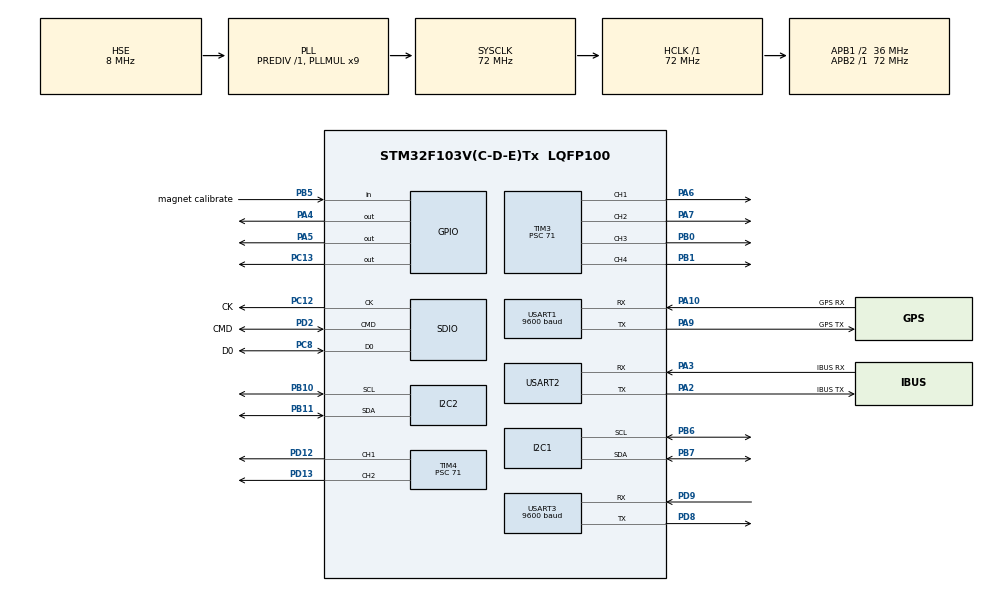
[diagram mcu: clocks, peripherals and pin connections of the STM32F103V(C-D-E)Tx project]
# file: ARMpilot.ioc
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Dma.Request0=USART2_RX
Dma.Request1=SDIO
Dma.SDIO.1.Direction=DMA_MEMORY_TO_PERIPH
Dma.SDIO.1.Instance=DMA2_Channel4
Dma.SDIO.1.MemDataAlignment=DMA_MDATAALIGN_WORD
Dma.SDIO.1.MemInc=DMA_MINC_ENABLE
Dma.SDIO.1.Mode=DMA_CIRCULAR
Dma.SDIO.1.PeriphDataAlignment=DMA_PDATAALIGN_WORD
Dma.SDIO.1.PeriphInc=DMA_PINC_DISABLE
Dma.SDIO.1.Priority=DMA_PRIORITY_LOW
Dma.USART2_RX.0.Direction=DMA_PERIPH_TO_MEMORY
Dma.USART2_RX.0.Instance=DMA1_Channel6
Dma.USART2_RX.0.MemDataAlignment=DMA_MDATAALIGN_BYTE
Dma.USART2_RX.0.MemInc=DMA_MINC_ENABLE
Dma.USART2_RX.0.Mode=DMA_CIRCULAR
Dma.USART2_RX.0.PeriphDataAlignment=DMA_PDATAALIGN_BYTE
Dma.USART2_RX.0.PeriphInc=DMA_PINC_DISABLE
Dma.USART2_RX.0.Priority=DMA_PRIORITY_LOW
FATFS._MAX_SS=4096
FATFS._MIN_SS=512
FATFS._USE_LFN=1
I2C1.I2C_Mode=I2C_Fast
I2C2.I2C_Mode=I2C_Fast
Mcu.Family=STM32F1
Mcu.Name=STM32F103V(C-D-E)Tx
Mcu.Package=LQFP100
NVIC.DMA1_Channel6_IRQn=true\:0\:0\:false\:false\:true\:false\:true\:true
NVIC.DMA2_Channel4_5_IRQn=true\:0\:0\:false\:false\:true\:false\:true\:true
NVIC.PriorityGroup=NVIC_PRIORITYGROUP_4
NVIC.SDIO_IRQn=true\:0\:0\:false\:false\:true\:true\:true\:true
NVIC.TIM6_IRQn=true\:0\:0\:false\:false\:true\:true\:true\:true
NVIC.TIM7_IRQn=true\:5\:0\:true\:false\:true\:true\:true\:true
NVIC.USART1_IRQn=true\:1\:0\:true\:false\:true\:true\:true\:true
NVIC.USART2_IRQn=true\:1\:0\:true\:false\:true\:true\:true\:true
NVIC.USART3_IRQn=true\:1\:0\:true\:false\:true\:true\:true\:true
OSC_IN.Mode=HSE-External-Oscillator
OSC_IN.Signal=RCC_OSC_IN
OSC_OUT.Mode=HSE-External-Oscillator
OSC_OUT.Signal=RCC_OSC_OUT
PA10.GPIO_Label=GPS RX
PA10.Mode=Asynchronous
PA10.Signal=USART1_RX
PA13.Mode=Serial_Wire
PA13.Signal=SYS_JTMS-SWDIO
PA14.Mode=Serial_Wire
PA14.Signal=SYS_JTCK-SWCLK
PA2.GPIO_Label=IBUS TX
PA2.Mode=Asynchronous
PA2.Signal=USART2_TX
PA3.GPIO_Label=IBUS RX
PA3.Mode=Asynchronous
PA3.Signal=USART2_RX
PA4.Signal=GPIO_Output
PA5.Signal=GPIO_Output
PA6.Signal=S_TIM3_CH1
PA7.Signal=S_TIM3_CH2
PA9.GPIO_Label=GPS TX
PA9.Mode=Asynchronous
PA9.Signal=USART1_TX
PB0.Signal=S_TIM3_CH3
PB1.Signal=S_TIM3_CH4
PB10.Mode=I2C
PB10.Signal=I2C2_SCL
PB11.Mode=I2C
PB11.Signal=I2C2_SDA
PB5.GPIO_Label=magnet calibrate
PB5.GPIO_PuPd=GPIO_PULLDOWN
PB5.Signal=GPIO_Input
PB6.Mode=I2C
PB6.Signal=I2C1_SCL
PB7.Mode=I2C
PB7.Signal=I2C1_SDA
PC12.GPIO_Label=CK
PC12.Mode=SD_1_bit
PC12.Signal=SDIO_CK
PC13-TAMPER-RTC.Signal=GPIO_Output
PC8.GPIO_Label=D0
PC8.Mode=SD_1_bit
PC8.Signal=SDIO_D0
PD12.Signal=S_TIM4_CH1
PD13.Signal=S_TIM4_CH2
PD2.GPIO_Label=CMD
PD2.Mode=SD_1_bit
PD2.Signal=SDIO_CMD
PD8.Mode=Asynchronous
PD8.Signal=USART3_TX
PD9.Mode=Asynchronous
PD9.Signal=USART3_RX
ProjectManager.HeapSize=0x1000
ProjectManager.StackSize=0x2000
ProjectManager.TargetToolchain=MDK-ARM V5.32
RCC.AHBFreq_Value=72000000
RCC.APB1CLKDivider=RCC_HCLK_DIV2
RCC.APB1Freq_Value=36000000
RCC.APB1TimFreq_Value=72000000
RCC.APB2Freq_Value=72000000
RCC.APB2TimFreq_Value=72000000
RCC.HCLKFreq_Value=72000000
RCC.PLLMUL=RCC_PLL_MUL9
RCC.PLLSourceVirtual=RCC_PLLSOURCE_HSE
RCC.SYSCLKFreq_VALUE=72000000
RCC.SYSCLKSource=RCC_SYSCLKSOURCE_PLLCLK
RCC.USBFreq_Value=72000000
SDIO.ClockDiv=2
SH.S_TIM3_CH1.0=TIM3_CH1,PWM Generation1 CH1
SH.S_TIM3_CH2.0=TIM3_CH2,PWM Generation2 CH2
SH.S_TIM3_CH3.0=TIM3_CH3,PWM Generation3 CH3
SH.S_TIM3_CH4.0=TIM3_CH4,PWM Generation4 CH4
SH.S_TIM4_CH1.0=TIM4_CH1,PWM Generation1 CH1
SH.S_TIM4_CH2.0=TIM4_CH2,PWM Generation2 CH2
TIM3.Channel-PWM\ Generation1\ CH1=TIM_CHANNEL_1
TIM3.Channel-PWM\ Generation2\ CH2=TIM_CHANNEL_2
TIM3.Channel-PWM\ Generation3\ CH3=TIM_CHANNEL_3
TIM3.Channel-PWM\ Generation4\ CH4=TIM_CHANNEL_4
TIM3.Prescaler=71
TIM4.Channel-PWM\ Generation1\ CH1=TIM_CHANNEL_1
TIM4.Channel-PWM\ Generation2\ CH2=TIM_CHANNEL_2
TIM4.Prescaler=71
TIM6.AutoReloadPreload=TIM_AUTORELOAD_PRELOAD_ENABLE
TIM6.Prescaler=71
TIM7.AutoReloadPreload=TIM_AUTORELOAD_PRELOAD_ENABLE
TIM7.Prescaler=71
USART1.BaudRate=9600
USART1.VirtualMode=VM_ASYNC
USART2.VirtualMode=VM_ASYNC
USART3.BaudRate=9600
USART3.VirtualMode=VM_ASYNC
VP_FATFS_VS_SDIO.Mode=SDIO
VP_TIM3_VS_ClockSourceINT.Mode=Internal
VP_TIM4_VS_ClockSourceINT.Mode=Internal
VP_TIM6_VS_ClockSourceINT.Mode=Enable_Timer
VP_TIM7_VS_ClockSourceINT.Mode=Enable_Timer
board=custom

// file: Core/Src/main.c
/* USER CODE BEGIN Header */
/**
  ******************************************************************************
  * @file           : main.c
  * @brief          : Main program body
  ******************************************************************************
  * @attention
  *
  * Copyright (c) 2024 STMicroelectronics.
  * All rights reserved.
  *
  * This software is licensed under terms that can be found in the LICENSE file
  * in the root directory of this software component.
  * If no LICENSE file comes with this software, it is provided AS-IS.
  *
  ******************************************************************************
  */
/* USER CODE END Header */
#include "main.h"
#include "dma.h"
#include "fatfs.h"
#include "i2c.h"
#include "sdio.h"
#include "tim.h"
#include "usart.h"
#include "gpio.h"

/* USER CODE BEGIN Includes */
#include "plane.h"
//#include "timer.h"
/* USER CODE END Includes */

void SystemClock_Config(void);

/* USER CODE BEGIN 0 */
//uint32_t a,b;
//FIL fs_;
//FATFS _fs;
//uint8_t mount;
//int counttt;
/* USER CODE END 0 */

int main(void)
{

  /* MCU Configuration--------------------------------------------------------*/

  /* Reset of all peripherals, Initializes the Flash interface and the Systick. */
  HAL_Init();

  /* Configure the system clock */
  SystemClock_Config();

  /* Initialize all configured peripherals */
  MX_GPIO_Init();
  MX_DMA_Init();
  MX_I2C1_Init();
  MX_I2C2_Init();
  MX_TIM6_Init();
  MX_TIM7_Init();
  MX_USART1_UART_Init();
  MX_USART2_UART_Init();
  MX_USART3_UART_Init();
  MX_SDIO_SD_Init();
  MX_TIM3_Init();
  MX_TIM4_Init();
  MX_FATFS_Init();
  /* USER CODE BEGIN 2 */

//   timer_start(&htim7);
//   mount = f_mount(&_fs,"", 1);
//   f_open(&fs_,"today.txt", FA_CREATE_ALWAYS | FA_WRITE | FA_READ);
   main_loop();

  /* USER CODE END 2 */

  /* Infinite loop */
  while (1)
  {

    /* USER CODE BEGIN 3 */

//	  a = micros();
//	  f_puts("xin chao DMA 16/4/2024\n",&fs_);
//	  f_sync(&fs_);
//	  b= micros() - a;
//////
//	  if(mount != FR_OK){
//		  HAL_GPIO_TogglePin(GPIOA, GPIO_PIN_4);
//	  }
//	  else{
//	      HAL_GPIO_TogglePin(GPIOA, GPIO_PIN_5);
//	  }

//	  HAL_Delay(100);

  }
  /* USER CODE END 3 */
}

void SystemClock_Config(void)
{
  RCC_OscInitTypeDef RCC_OscInitStruct = {0};
  RCC_ClkInitTypeDef RCC_ClkInitStruct = {0};

  /** Initializes the RCC Oscillators according to the specified parameters
  * in the RCC_OscInitTypeDef structure.
  */
  RCC_OscInitStruct.OscillatorType = RCC_OSCILLATORTYPE_HSE;
  RCC_OscInitStruct.HSEState = RCC_HSE_ON;
  RCC_OscInitStruct.HSEPredivValue = RCC_HSE_PREDIV_DIV1;
  RCC_OscInitStruct.HSIState = RCC_HSI_ON;
  RCC_OscInitStruct.PLL.PLLState = RCC_PLL_ON;
  RCC_OscInitStruct.PLL.PLLSource = RCC_PLLSOURCE_HSE;
  RCC_OscInitStruct.PLL.PLLMUL = RCC_PLL_MUL9;
  if (HAL_RCC_OscConfig(&RCC_OscInitStruct) != HAL_OK)
  {
    Error_Handler();
  }

  /** Initializes the CPU, AHB and APB buses clocks
  */
  RCC_ClkInitStruct.ClockType = RCC_CLOCKTYPE_HCLK|RCC_CLOCKTYPE_SYSCLK
                              |RCC_CLOCKTYPE_PCLK1|RCC_CLOCKTYPE_PCLK2;
  RCC_ClkInitStruct.SYSCLKSource = RCC_SYSCLKSOURCE_PLLCLK;
  RCC_ClkInitStruct.AHBCLKDivider = RCC_SYSCLK_DIV1;
  RCC_ClkInitStruct.APB1CLKDivider = RCC_HCLK_DIV2;
  RCC_ClkInitStruct.APB2CLKDivider = RCC_HCLK_DIV1;

  if (HAL_RCC_ClockConfig(&RCC_ClkInitStruct, FLASH_LATENCY_2) != HAL_OK)
  {
    Error_Handler();
  }
}

void Error_Handler(void)
{
  __disable_irq();
  while (1)
  {
  }
}
